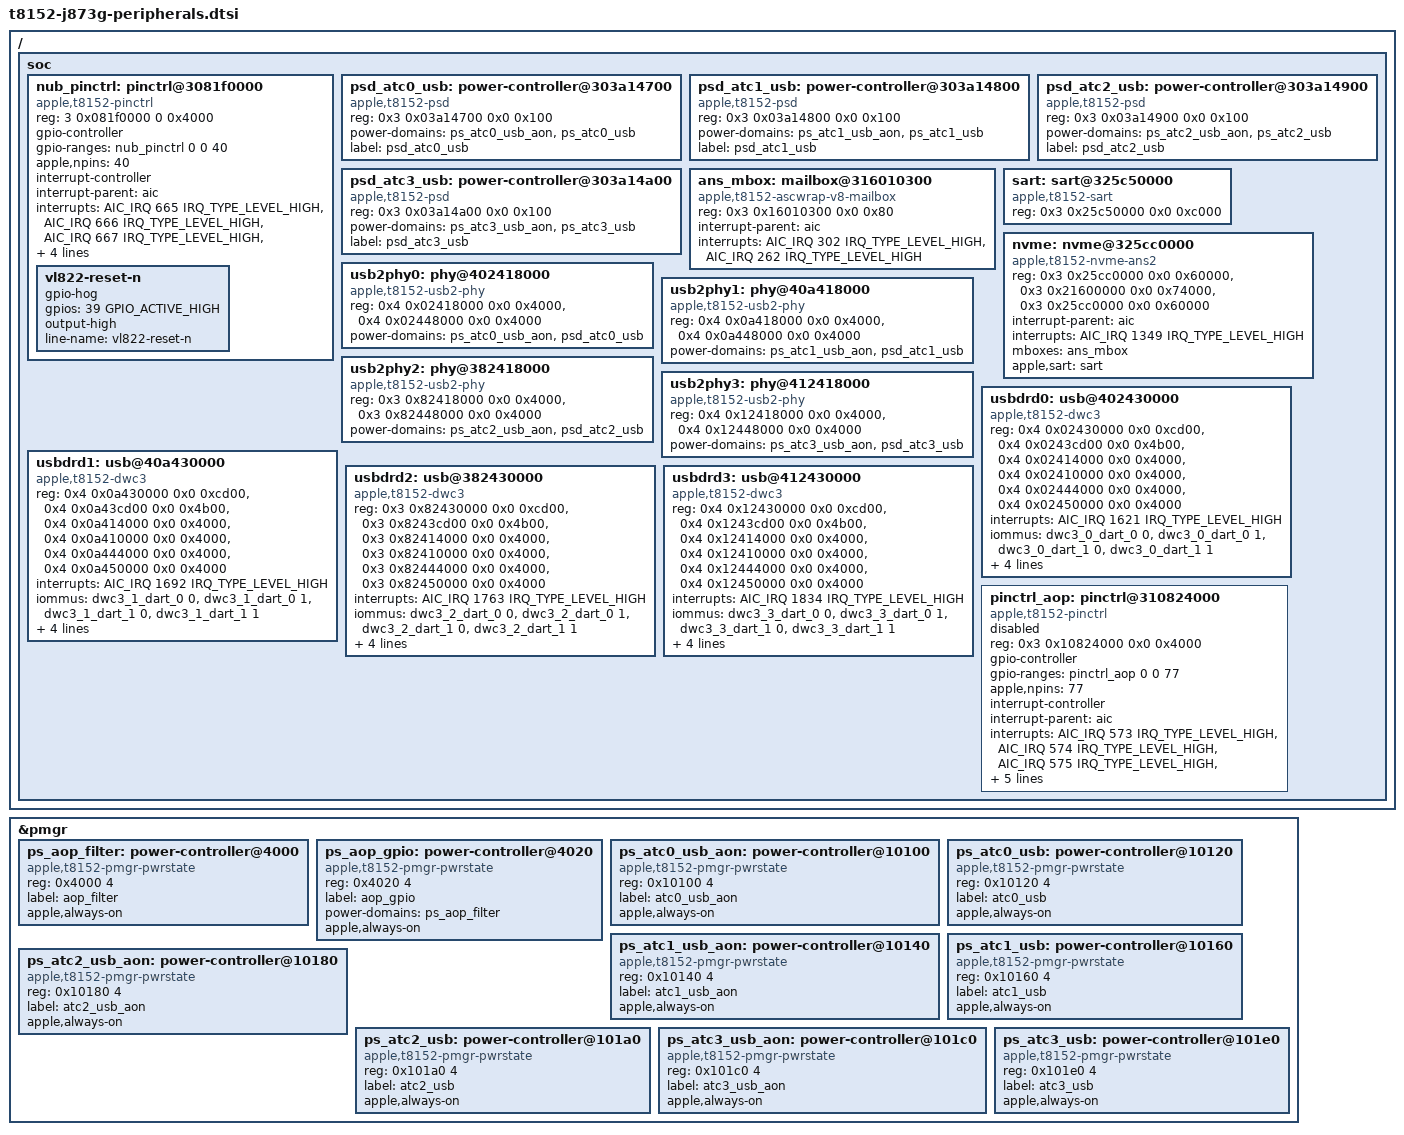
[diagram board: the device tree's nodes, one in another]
// SPDX-License-Identifier: GPL-2.0+ OR MIT
/*
 * Apple Mac mini (M6), J873g: peripherals that have a driver in this tree.
 *
 * Only addresses, interrupt numbers and wiring are described here. The boot
 * loader adds the register tunables that some of these blocks need. The
 * power-management (PMGR) domains are not described yet, so nodes that need
 * them are left out.
 */

#include <dt-bindings/gpio/gpio.h>

/ {
	soc {
		/*
		 * GPIO controller of the always-on block. Pin 39 releases
		 * the reset of the front-port USB hub.
		 */
		nub_pinctrl: pinctrl@3081f0000 {
			compatible = "apple,t8152-pinctrl", "apple,t8103-pinctrl";
			reg = <3 0x081f0000 0 0x4000>;
			gpio-controller;
			#gpio-cells = <2>;
			gpio-ranges = <&nub_pinctrl 0 0 40>;
			apple,npins = <40>;
			interrupt-controller;
			#interrupt-cells = <2>;
			interrupt-parent = <&aic>;
			interrupts = <AIC_IRQ 665 IRQ_TYPE_LEVEL_HIGH>,
				     <AIC_IRQ 666 IRQ_TYPE_LEVEL_HIGH>,
				     <AIC_IRQ 667 IRQ_TYPE_LEVEL_HIGH>,
				     <AIC_IRQ 668 IRQ_TYPE_LEVEL_HIGH>,
				     <AIC_IRQ 669 IRQ_TYPE_LEVEL_HIGH>,
				     <AIC_IRQ 670 IRQ_TYPE_LEVEL_HIGH>,
				     <AIC_IRQ 671 IRQ_TYPE_LEVEL_HIGH>;

			vl822-reset-n {
				gpio-hog;
				gpios = <39 GPIO_ACTIVE_HIGH>;
				output-high;
				line-name = "vl822-reset-n";
			};
		};

		/* Power state director: one service slot per USB port, 0x100 bytes each. */
		psd_atc0_usb: power-controller@303a14700 {
			compatible = "apple,t8152-psd";
			reg = <0x3 0x03a14700 0x0 0x100>;
			#power-domain-cells = <0>;
			power-domains = <&ps_atc0_usb_aon>, <&ps_atc0_usb>;
			label = "psd_atc0_usb";
		};

		psd_atc1_usb: power-controller@303a14800 {
			compatible = "apple,t8152-psd";
			reg = <0x3 0x03a14800 0x0 0x100>;
			#power-domain-cells = <0>;
			power-domains = <&ps_atc1_usb_aon>, <&ps_atc1_usb>;
			label = "psd_atc1_usb";
		};

		psd_atc2_usb: power-controller@303a14900 {
			compatible = "apple,t8152-psd";
			reg = <0x3 0x03a14900 0x0 0x100>;
			#power-domain-cells = <0>;
			power-domains = <&ps_atc2_usb_aon>, <&ps_atc2_usb>;
			label = "psd_atc2_usb";
		};

		psd_atc3_usb: power-controller@303a14a00 {
			compatible = "apple,t8152-psd";
			reg = <0x3 0x03a14a00 0x0 0x100>;
			#power-domain-cells = <0>;
			power-domains = <&ps_atc3_usb_aon>, <&ps_atc3_usb>;
			label = "psd_atc3_usb";
		};

		/*
		 * ANS NVMe storage: the coprocessor's post-office mailbox,
		 * its SART address filter and the controller itself. The boot
		 * loader leaves ANS powered, so no power domain is named.
		 */
		ans_mbox: mailbox@316010300 {
			compatible = "apple,t8152-ascwrap-v8-mailbox";
			reg = <0x3 0x16010300 0x0 0x80>;
			interrupt-parent = <&aic>;
			interrupts = <AIC_IRQ 302 IRQ_TYPE_LEVEL_HIGH>,
				     <AIC_IRQ 262 IRQ_TYPE_LEVEL_HIGH>;
			interrupt-names = "send-empty", "recv-not-empty";
			#mbox-cells = <0>;
		};

		sart: sart@325c50000 {
			compatible = "apple,t8152-sart";
			reg = <0x3 0x25c50000 0x0 0xc000>;
		};

		nvme: nvme@325cc0000 {
			compatible = "apple,t8152-nvme-ans2",
				     "apple,t8132-nvme-ans2";
			reg = <0x3 0x25cc0000 0x0 0x60000>,
			      <0x3 0x21600000 0x0 0x74000>,
			      <0x3 0x25cc0000 0x0 0x60000>;
			reg-names = "nvme", "ans", "nvmmu";
			interrupt-parent = <&aic>;
			interrupts = <AIC_IRQ 1349 IRQ_TYPE_LEVEL_HIGH>;
			mboxes = <&ans_mbox>;
			apple,sart = <&sart>;
		};

		/*
		 * The USB2 side of each ATC port: one PHY per DWC3 controller.
		 * Each sits behind its port's always-on and PSD domains. The
		 * SuperSpeed side of the ATC PHY is not described yet.
		 */
		usb2phy0: phy@402418000 {
			compatible = "apple,t8152-usb2-phy";
			reg = <0x4 0x02418000 0x0 0x4000>,
			      <0x4 0x02448000 0x0 0x4000>;
			reg-names = "usb2", "eusb2";
			#phy-cells = <0>;
			power-domains = <&ps_atc0_usb_aon>, <&psd_atc0_usb>;
			power-domain-names = "usb-aon", "usb";
		};

		usb2phy1: phy@40a418000 {
			compatible = "apple,t8152-usb2-phy";
			reg = <0x4 0x0a418000 0x0 0x4000>,
			      <0x4 0x0a448000 0x0 0x4000>;
			reg-names = "usb2", "eusb2";
			#phy-cells = <0>;
			power-domains = <&ps_atc1_usb_aon>, <&psd_atc1_usb>;
			power-domain-names = "usb-aon", "usb";
		};

		usb2phy2: phy@382418000 {
			compatible = "apple,t8152-usb2-phy";
			reg = <0x3 0x82418000 0x0 0x4000>,
			      <0x3 0x82448000 0x0 0x4000>;
			reg-names = "usb2", "eusb2";
			#phy-cells = <0>;
			power-domains = <&ps_atc2_usb_aon>, <&psd_atc2_usb>;
			power-domain-names = "usb-aon", "usb";
		};

		usb2phy3: phy@412418000 {
			compatible = "apple,t8152-usb2-phy";
			reg = <0x4 0x12418000 0x0 0x4000>,
			      <0x4 0x12448000 0x0 0x4000>;
			reg-names = "usb2", "eusb2";
			#phy-cells = <0>;
			power-domains = <&ps_atc3_usb_aon>, <&psd_atc3_usb>;
			power-domain-names = "usb-aon", "usb";
		};

		/*
		 * The four DWC3 controllers, one per ATC port. Port 0 is the
		 * debug-cable port and stays a fixed peripheral; the other
		 * three are fixed hosts. Each maps two stream IDs on each of
		 * its two DART instances. All are USB2-only for now.
		 */
		usbdrd0: usb@402430000 {
			compatible = "apple,t8152-dwc3";
			reg = <0x4 0x02430000 0x0 0xcd00>,
			      <0x4 0x0243cd00 0x0 0x4b00>,
			      <0x4 0x02414000 0x0 0x4000>,
			      <0x4 0x02410000 0x0 0x4000>,
			      <0x4 0x02444000 0x0 0x4000>,
			      <0x4 0x02450000 0x0 0x4000>;
			reg-names = "dwc3-core", "dwc3-apple", "pipe-handler",
				    "pwr-ctrl", "bulk-fabric", "ausbc-debug";
			interrupts = <AIC_IRQ 1621 IRQ_TYPE_LEVEL_HIGH>;
			iommus = <&dwc3_0_dart_0 0>, <&dwc3_0_dart_0 1>,
				 <&dwc3_0_dart_1 0>, <&dwc3_0_dart_1 1>;
			power-domains = <&psd_atc0_usb>;
			phys = <&usb2phy0>;
			phy-names = "usb2-phy";
			dr_mode = "peripheral";
			maximum-speed = "high-speed";
		};

		usbdrd1: usb@40a430000 {
			compatible = "apple,t8152-dwc3";
			reg = <0x4 0x0a430000 0x0 0xcd00>,
			      <0x4 0x0a43cd00 0x0 0x4b00>,
			      <0x4 0x0a414000 0x0 0x4000>,
			      <0x4 0x0a410000 0x0 0x4000>,
			      <0x4 0x0a444000 0x0 0x4000>,
			      <0x4 0x0a450000 0x0 0x4000>;
			reg-names = "dwc3-core", "dwc3-apple", "pipe-handler",
				    "pwr-ctrl", "bulk-fabric", "ausbc-debug";
			interrupts = <AIC_IRQ 1692 IRQ_TYPE_LEVEL_HIGH>;
			iommus = <&dwc3_1_dart_0 0>, <&dwc3_1_dart_0 1>,
				 <&dwc3_1_dart_1 0>, <&dwc3_1_dart_1 1>;
			power-domains = <&psd_atc1_usb>;
			phys = <&usb2phy1>;
			phy-names = "usb2-phy";
			dr_mode = "host";
			maximum-speed = "high-speed";
		};

		usbdrd2: usb@382430000 {
			compatible = "apple,t8152-dwc3";
			reg = <0x3 0x82430000 0x0 0xcd00>,
			      <0x3 0x8243cd00 0x0 0x4b00>,
			      <0x3 0x82414000 0x0 0x4000>,
			      <0x3 0x82410000 0x0 0x4000>,
			      <0x3 0x82444000 0x0 0x4000>,
			      <0x3 0x82450000 0x0 0x4000>;
			reg-names = "dwc3-core", "dwc3-apple", "pipe-handler",
				    "pwr-ctrl", "bulk-fabric", "ausbc-debug";
			interrupts = <AIC_IRQ 1763 IRQ_TYPE_LEVEL_HIGH>;
			iommus = <&dwc3_2_dart_0 0>, <&dwc3_2_dart_0 1>,
				 <&dwc3_2_dart_1 0>, <&dwc3_2_dart_1 1>;
			power-domains = <&psd_atc2_usb>;
			phys = <&usb2phy2>;
			phy-names = "usb2-phy";
			dr_mode = "host";
			maximum-speed = "high-speed";
		};

		usbdrd3: usb@412430000 {
			compatible = "apple,t8152-dwc3";
			reg = <0x4 0x12430000 0x0 0xcd00>,
			      <0x4 0x1243cd00 0x0 0x4b00>,
			      <0x4 0x12414000 0x0 0x4000>,
			      <0x4 0x12410000 0x0 0x4000>,
			      <0x4 0x12444000 0x0 0x4000>,
			      <0x4 0x12450000 0x0 0x4000>;
			reg-names = "dwc3-core", "dwc3-apple", "pipe-handler",
				    "pwr-ctrl", "bulk-fabric", "ausbc-debug";
			interrupts = <AIC_IRQ 1834 IRQ_TYPE_LEVEL_HIGH>;
			iommus = <&dwc3_3_dart_0 0>, <&dwc3_3_dart_0 1>,
				 <&dwc3_3_dart_1 0>, <&dwc3_3_dart_1 1>;
			power-domains = <&psd_atc3_usb>;
			phys = <&usb2phy3>;
			phy-names = "usb2-phy";
			dr_mode = "host";
			maximum-speed = "high-speed";
		};

		/* ADT /arm-io/aop-gpio; coprocessor/firmware ownership unqualified. */
		pinctrl_aop: pinctrl@310824000 {
			compatible = "apple,t8152-pinctrl", "apple,t8103-pinctrl";
			reg = <0x3 0x10824000 0x0 0x4000>;
			gpio-controller;
			#gpio-cells = <2>;
			gpio-ranges = <&pinctrl_aop 0 0 77>;
			apple,npins = <77>;
			interrupt-controller;
			#interrupt-cells = <2>;
			interrupt-parent = <&aic>;
			interrupts = <AIC_IRQ 573 IRQ_TYPE_LEVEL_HIGH>,
				     <AIC_IRQ 574 IRQ_TYPE_LEVEL_HIGH>,
				     <AIC_IRQ 575 IRQ_TYPE_LEVEL_HIGH>,
				     <AIC_IRQ 576 IRQ_TYPE_LEVEL_HIGH>,
				     <AIC_IRQ 577 IRQ_TYPE_LEVEL_HIGH>,
				     <AIC_IRQ 578 IRQ_TYPE_LEVEL_HIGH>,
				     <AIC_IRQ 579 IRQ_TYPE_LEVEL_HIGH>;
			power-domains = <&ps_aop_gpio>;
			status = "disabled";
		};
	};
};

/* The ATC USB domains, one always-on and one main pair per port. */
&pmgr {
	ps_aop_filter: power-controller@4000 {
		compatible = "apple,t8152-pmgr-pwrstate",
			     "apple,t8103-pmgr-pwrstate";
		reg = <0x4000 4>;
		#power-domain-cells = <0>;
		#reset-cells = <0>;
		label = "aop_filter";
		apple,always-on;
	};

	ps_aop_gpio: power-controller@4020 {
		compatible = "apple,t8152-pmgr-pwrstate",
			     "apple,t8103-pmgr-pwrstate";
		reg = <0x4020 4>;
		#power-domain-cells = <0>;
		#reset-cells = <0>;
		label = "aop_gpio";
		power-domains = <&ps_aop_filter>;
		apple,always-on;
	};

	ps_atc0_usb_aon: power-controller@10100 {
		compatible = "apple,t8152-pmgr-pwrstate",
			     "apple,t8103-pmgr-pwrstate";
		reg = <0x10100 4>;
		#power-domain-cells = <0>;
		#reset-cells = <0>;
		label = "atc0_usb_aon";
		apple,always-on;
	};

	ps_atc0_usb: power-controller@10120 {
		compatible = "apple,t8152-pmgr-pwrstate",
			     "apple,t8103-pmgr-pwrstate";
		reg = <0x10120 4>;
		#power-domain-cells = <0>;
		#reset-cells = <0>;
		label = "atc0_usb";
		apple,always-on;
	};

	ps_atc1_usb_aon: power-controller@10140 {
		compatible = "apple,t8152-pmgr-pwrstate",
			     "apple,t8103-pmgr-pwrstate";
		reg = <0x10140 4>;
		#power-domain-cells = <0>;
		#reset-cells = <0>;
		label = "atc1_usb_aon";
		apple,always-on;
	};

	ps_atc1_usb: power-controller@10160 {
		compatible = "apple,t8152-pmgr-pwrstate",
			     "apple,t8103-pmgr-pwrstate";
		reg = <0x10160 4>;
		#power-domain-cells = <0>;
		#reset-cells = <0>;
		label = "atc1_usb";
		apple,always-on;
	};

	ps_atc2_usb_aon: power-controller@10180 {
		compatible = "apple,t8152-pmgr-pwrstate",
			     "apple,t8103-pmgr-pwrstate";
		reg = <0x10180 4>;
		#power-domain-cells = <0>;
		#reset-cells = <0>;
		label = "atc2_usb_aon";
		apple,always-on;
	};

	ps_atc2_usb: power-controller@101a0 {
		compatible = "apple,t8152-pmgr-pwrstate",
			     "apple,t8103-pmgr-pwrstate";
		reg = <0x101a0 4>;
		#power-domain-cells = <0>;
		#reset-cells = <0>;
		label = "atc2_usb";
		apple,always-on;
	};

	ps_atc3_usb_aon: power-controller@101c0 {
		compatible = "apple,t8152-pmgr-pwrstate",
			     "apple,t8103-pmgr-pwrstate";
		reg = <0x101c0 4>;
		#power-domain-cells = <0>;
		#reset-cells = <0>;
		label = "atc3_usb_aon";
		apple,always-on;
	};

	ps_atc3_usb: power-controller@101e0 {
		compatible = "apple,t8152-pmgr-pwrstate",
			     "apple,t8103-pmgr-pwrstate";
		reg = <0x101e0 4>;
		#power-domain-cells = <0>;
		#reset-cells = <0>;
		label = "atc3_usb";
		apple,always-on;
	};
};
